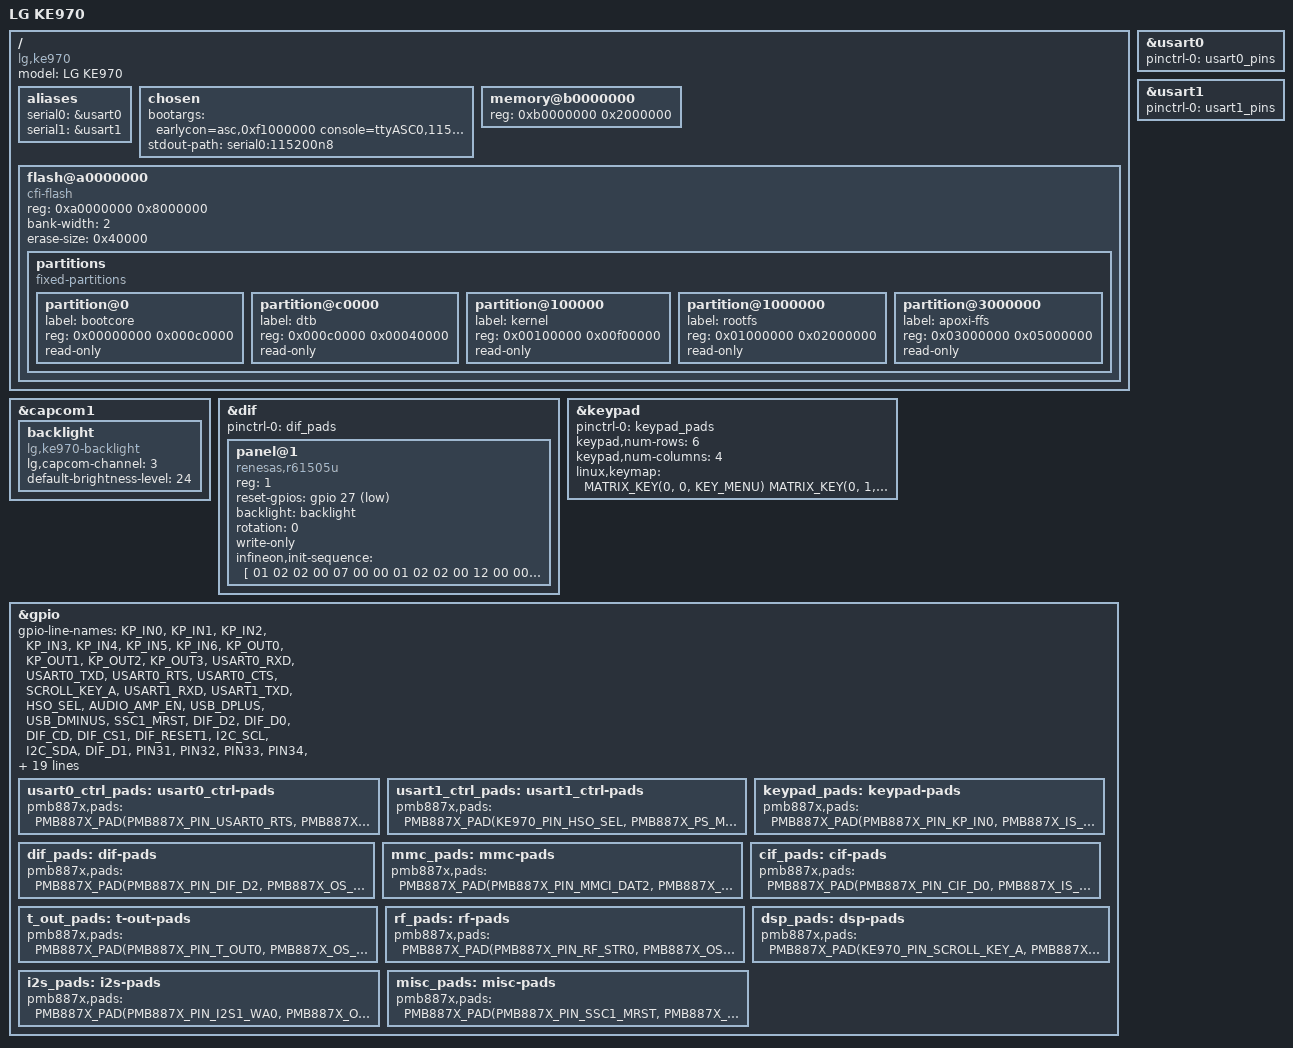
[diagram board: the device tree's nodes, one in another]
// SPDX-License-Identifier: GPL-2.0
/dts-v1/;
#include "pmb8876.dtsi"

#include <dt-bindings/gpio/gpio.h>
#include <dt-bindings/input/input.h>
#include <dt-bindings/pinctrl/pmb887x.h>
#include "ke970-pins.h"

/ {
	model = "LG KE970";
	compatible = "lg,ke970", "infineon,pmb8876";
	
	aliases {
		serial0 = &usart0;
		serial1 = &usart1;
	};
	
	chosen {
		bootargs = "earlycon=asc,0xf1000000 console=ttyASC0,115200n8 ignore_loglevel root=mtd:rootfs rootfstype=cramfs ro";
		stdout-path = "serial0:115200n8";
	};
	
	/* RAM */
	memory@b0000000 {
		device_type = "memory";
		reg = <0xb0000000 0x2000000>;
	};

	/* NOR Flash */
	flash@a0000000 {
		compatible = "cfi-flash";
		reg = <0xa0000000 0x8000000>;
		bank-width = <2>;
		erase-size = <0x40000>;

		partitions {
			compatible = "fixed-partitions";
			#address-cells = <1>;
			#size-cells = <1>;

			partition@0 {
				label = "bootcore";
				reg = <0x00000000 0x000c0000>;
				read-only;
			};

			partition@c0000 {
				label = "dtb";
				reg = <0x000c0000 0x00040000>;
				read-only;
			};

			partition@100000 {
				label = "kernel";
				reg = <0x00100000 0x00f00000>;
				read-only;
			};

			partition@1000000 {
				label = "rootfs";
				reg = <0x01000000 0x02000000>;
				read-only;
			};

			partition@3000000 {
				label = "apoxi-ffs";
				reg = <0x03000000 0x05000000>;
				read-only;
			};
		};
	};
};

/* Usart at "nano" connector */
&usart0 {
	status = "okay";
	pinctrl-names = "default";
	pinctrl-0 = <&usart0_pins>;
};

/* Usart for debug */
&usart1 {
	status = "okay";
	pinctrl-names = "default";
	pinctrl-0 = <&usart1_pins>;
};

/* MAX8645Y single-wire pulse dimming on CC3, pad LCD_BACKLIGHT (ALT2 output) */
&capcom1 {
	backlight: backlight {
		compatible = "lg,ke970-backlight";
		lg,capcom-channel = <3>;
		default-brightness-level = <24>;
	};
};

/* IL220 module: 240x320 R61505U (ILI9320-class) controller on DIF CS1. */
&dif {
	status = "okay";
	pinctrl-names = "default";
	pinctrl-0 = <&dif_pads>;

	panel@1 {
		compatible = "renesas,r61505u";
		reg = <1>;
		reset-gpios = <&gpio 27 GPIO_ACTIVE_LOW>;
		backlight = <&backlight>;
		rotation = <0>;
		write-only;
		infineon,init-sequence = [
			01 02 02 00 07 00 00       /* R07 = 0x0000 */
			01 02 02 00 12 00 00       /* R12 = 0x0000 */
			02 09                      /* wait 9 ms */
			01 02 00 00 00             /* R00 index write (oscillator wake-up) */
			01 02 00 00 00             /* R00 index write (oscillator wake-up) */
			01 02 00 00 00             /* R00 index write (oscillator wake-up) */
			01 02 00 00 00             /* R00 index write (oscillator wake-up) */
			01 02 02 00 00 00 01       /* R00 = 0x0001 (OSC on) */
			02 0a                      /* wait 10 ms */
			01 02 02 00 a4 00 01       /* RA4 = 0x0001 */
			01 02 02 00 60 27 00       /* R60 = 0x2700 */
			01 02 02 00 08 02 0e       /* R08 = 0x020E */
			01 02 02 00 30 07 00       /* R30 = 0x0700 */
			01 02 02 00 31 02 00       /* R31 = 0x0200 */
			01 02 02 00 32 02 02       /* R32 = 0x0202 */
			01 02 02 00 33 00 03       /* R33 = 0x0003 */
			01 02 02 00 34 03 03       /* R34 = 0x0303 */
			01 02 02 00 35 07 07       /* R35 = 0x0707 */
			01 02 02 00 36 1f 1f       /* R36 = 0x1F1F */
			01 02 02 00 37 05 06       /* R37 = 0x0506 */
			01 02 02 00 38 02 02       /* R38 = 0x0202 */
			01 02 02 00 39 02 02       /* R39 = 0x0202 */
			01 02 02 00 3a 01 03       /* R3A = 0x0103 */
			01 02 02 00 3b 03 03       /* R3B = 0x0303 */
			01 02 02 00 3c 07 03       /* R3C = 0x0703 */
			01 02 02 00 3d 1f 1f       /* R3D = 0x1F1F */
			02 09                      /* wait 9 ms */
			01 02 02 00 07 00 01       /* R07 = 0x0001 */
			01 02 02 00 17 00 01       /* R17 = 0x0001 */
			01 02 02 00 10 10 b0       /* R10 = 0x10B0 */
			01 02 02 00 11 01 17       /* R11 = 0x0117 */
			01 02 02 00 12 01 1a       /* R12 = 0x011A */
			01 02 02 00 13 0a 00       /* R13 = 0x0A00 */
			01 02 02 00 29 00 0b       /* R29 = 0x000B */
			01 02 02 00 12 01 3a       /* R12 = 0x013A */
			01 02 02 00 01 05 00       /* R01 = 0x0500 */
			01 02 02 00 02 07 00       /* R02 = 0x0700 */
			01 02 02 00 03 50 30       /* R03 = 0x5030 */
			01 02 02 00 04 00 00       /* R04 = 0x0000 */
			01 02 02 00 09 00 01       /* R09 = 0x0001 */
			01 02 02 00 0a 00 08       /* R0A = 0x0008 */
			01 02 02 00 0d 00 0e       /* R0D = 0x000E */
			01 02 02 00 50 00 00       /* R50 = 0x0000 */
			01 02 02 00 51 00 ef       /* R51 = 0x00EF */
			01 02 02 00 52 00 00       /* R52 = 0x0000 */
			01 02 02 00 53 01 3f       /* R53 = 0x013F */
			01 02 02 00 61 00 00       /* R61 = 0x0000 */
			01 02 02 00 90 00 1c       /* R90 = 0x001C */
			01 02 02 00 92 01 00       /* R92 = 0x0100 */
			01 02 02 00 93 00 02       /* R93 = 0x0002 */
			01 02 02 00 20 00 00       /* R20 = 0x0000 */
			01 02 02 00 21 00 00       /* R21 = 0x0000 */
			01 02 02 00 07 00 21       /* R07 = 0x0021 */
			02 0a                      /* wait 10 ms */
			01 02 02 00 07 00 61       /* R07 = 0x0061 (display on, VCOM output) */
			02 06                      /* wait 6 ms */
			01 02 02 00 07 01 73       /* R07 = 0x0173 (display on, VCOM output) */
		];
	};
};

/*
 * 6x5 matrix on KP_IN0..5 and KP_OUT0..4, where the fifth column is not a
 * KP_OUT pad but T_OUT7 in its ALT1 output function, configured over in
 * t_out_pads. That column carries only the second stage of the camera side
 * key, so it is left out of the keymap for now; adding it means bumping
 * keypad,num-columns to 5 and mapping (5, 4) to KEY_CAMERA.
 */
&keypad {
	status = "okay";
	pinctrl-names = "default";
	pinctrl-0 = <&keypad_pads>;

	keypad,num-rows = <6>;
	keypad,num-columns = <4>;

	linux,keymap = <
		MATRIX_KEY(0, 0, KEY_MENU)		/* left soft key */
		MATRIX_KEY(0, 1, KEY_ENTER)		/* OK */
		MATRIX_KEY(0, 2, KEY_SEARCH)		/* right soft key */
		MATRIX_KEY(0, 3, KEY_SEND)

		MATRIX_KEY(1, 0, KEY_1)
		MATRIX_KEY(1, 1, KEY_2)
		MATRIX_KEY(1, 2, KEY_3)
		MATRIX_KEY(1, 3, KEY_BACKSPACE)		/* clear */

		MATRIX_KEY(2, 0, KEY_4)
		MATRIX_KEY(2, 1, KEY_5)
		MATRIX_KEY(2, 2, KEY_6)
		MATRIX_KEY(2, 3, KEY_VOLUMEUP)

		MATRIX_KEY(3, 0, KEY_7)
		MATRIX_KEY(3, 1, KEY_8)
		MATRIX_KEY(3, 2, KEY_9)
		MATRIX_KEY(3, 3, KEY_VOLUMEDOWN)

		MATRIX_KEY(4, 0, KEY_NUMERIC_STAR)
		MATRIX_KEY(4, 1, KEY_0)
		MATRIX_KEY(4, 2, KEY_NUMERIC_POUND)
		MATRIX_KEY(4, 3, KEY_MEDIA)		/* music player */

		MATRIX_KEY(5, 0, KEY_LEFT)
		MATRIX_KEY(5, 1, KEY_POWER)		/* end call, also drives PMIC ON */
		MATRIX_KEY(5, 2, KEY_RIGHT)
		MATRIX_KEY(5, 3, KEY_CAMERA_FOCUS)	/* camera side key, half press */
	>;
};

&gpio {
	gpio-line-names = "KP_IN0", "KP_IN1", "KP_IN2", "KP_IN3", "KP_IN4", "KP_IN5", "KP_IN6", "KP_OUT0", "KP_OUT1",
		"KP_OUT2", "KP_OUT3", "USART0_RXD", "USART0_TXD", "USART0_RTS", "USART0_CTS", "SCROLL_KEY_A",
		"USART1_RXD", "USART1_TXD", "HSO_SEL", "AUDIO_AMP_EN", "USB_DPLUS", "USB_DMINUS", "SSC1_MRST",
		"DIF_D2", "DIF_D0", "DIF_CD", "DIF_CS1", "DIF_RESET1", "I2C_SCL", "I2C_SDA", "DIF_D1", "PIN31",
		"PIN32", "PIN33", "PIN34", "PIN35", "PIN36", "PIN37", "I2S1_WA0", "USB_CHG_EN", "MMCI_DAT2",
		"MMCI_DAT3", "PIN42", "T_OUT0", "T_OUT1", "T_OUT2", "T_OUT3", "T_OUT4", "T_OUT5", "T_OUT6", "T_OUT7",
		"JACK_DETECT", "LCD_BACKLIGHT", "T_OUT10", "T_OUT11", "AF_PWR_EN", "RF_STR0", "RF_STR1", "SLIDE_OPEN",
		"RF_CLK", "PIN60", "BT_RESET", "SCROLL_KEY_B", "SIM_EN", "PIN64", "PIN65", "PIPESTAT2", "PIPESTAT1",
		"PIPESTAT0", "TRACEPKT0", "TRACEPKT1", "TRACEPKT2", "TRACEPKT3", "TRACEPKT4", "PIN74", "PIN75", "PIN76",
		"FCDP_RB", "CIF_D0", "CIF_D1", "CIF_D2", "CIF_D3", "CIF_D4", "CIF_D5", "CIF_D6", "CIF_D7", "CIF_PCLK",
		"CIF_HSYNC", "CIF_VSYNC", "CLKOUT2", "CIF_RESET", "DIF_D3", "DIF_D4", "DIF_D5", "DIF_D6", "DIF_D7",
		"LCD_IF_MODE", "DIF_WR", "HOOK_DETECT", "MMCI_DAT1", "DIF_VD", "PIN101", "PIN102",
		"SLIDE_KEY_BACKLIGHT", "MMCI_CMD", "MMCI_DAT0", "MMCI_CLK", "USIF_TXD_MTSR", "PIN108", "SCROLL_EN",
		"RPWRON", "SPK_RCV_SEL", "I2S1_CLK1", "CIF_PD";

	usart0_ctrl_pads: usart0_ctrl-pads {
		pmb887x,pads = <
			PMB887X_PAD(PMB887X_PIN_USART0_RTS, PMB887X_ENAQ_ON)
			PMB887X_PAD(PMB887X_PIN_USART0_CTS, PMB887X_IS_ALT0 | PMB887X_PPEN_OPENDRAIN | PMB887X_PDPU_PULLUP)
		>;
	};

	usart1_ctrl_pads: usart1_ctrl-pads {
		pmb887x,pads = <
			PMB887X_PAD(KE970_PIN_HSO_SEL, PMB887X_PS_MANUAL | PMB887X_DATA_HIGH | PMB887X_DIR_OUT | PMB887X_PDPU_PULLUP)
			PMB887X_PAD(KE970_PIN_AUDIO_AMP_EN, PMB887X_PS_MANUAL | PMB887X_DATA_HIGH | PMB887X_DIR_OUT | PMB887X_PDPU_PULLUP)
		>;
	};

	keypad_pads: keypad-pads {
		pmb887x,pads = <
			PMB887X_PAD(PMB887X_PIN_KP_IN0, PMB887X_IS_ALT0 | PMB887X_PPEN_OPENDRAIN | PMB887X_PDPU_PULLUP)
			PMB887X_PAD(PMB887X_PIN_KP_IN1, PMB887X_IS_ALT0 | PMB887X_PPEN_OPENDRAIN | PMB887X_PDPU_PULLUP)
			PMB887X_PAD(PMB887X_PIN_KP_IN2, PMB887X_IS_ALT0 | PMB887X_PPEN_OPENDRAIN | PMB887X_PDPU_PULLUP)
			PMB887X_PAD(PMB887X_PIN_KP_IN3, PMB887X_IS_ALT0 | PMB887X_PPEN_OPENDRAIN | PMB887X_PDPU_PULLUP)
			PMB887X_PAD(PMB887X_PIN_KP_IN4, PMB887X_IS_ALT0 | PMB887X_PPEN_OPENDRAIN | PMB887X_PDPU_PULLUP)
			PMB887X_PAD(PMB887X_PIN_KP_IN5, PMB887X_IS_ALT0 | PMB887X_PPEN_OPENDRAIN | PMB887X_PDPU_PULLUP)
			PMB887X_PAD(PMB887X_PIN_KP_IN6, PMB887X_PS_MANUAL | PMB887X_DIR_OUT)
			PMB887X_PAD(PMB887X_PIN_KP_OUT0, PMB887X_OS_ALT0 | PMB887X_PPEN_OPENDRAIN)
			PMB887X_PAD(PMB887X_PIN_KP_OUT1, PMB887X_OS_ALT0 | PMB887X_PPEN_OPENDRAIN)
			PMB887X_PAD(PMB887X_PIN_KP_OUT2, PMB887X_OS_ALT0 | PMB887X_PPEN_OPENDRAIN)
			PMB887X_PAD(PMB887X_PIN_KP_OUT3, PMB887X_OS_ALT0 | PMB887X_PPEN_OPENDRAIN)
		>;
	};

	dif_pads: dif-pads {
		pmb887x,pads = <
			PMB887X_PAD(PMB887X_PIN_DIF_D2, PMB887X_OS_ALT0 | PMB887X_PDPU_PULLUP)
			PMB887X_PAD(PMB887X_PIN_DIF_D0, PMB887X_OS_ALT0 | PMB887X_PDPU_PULLUP)
			PMB887X_PAD(PMB887X_PIN_DIF_CD, PMB887X_OS_ALT0 | PMB887X_PDPU_PULLUP)
			PMB887X_PAD(PMB887X_PIN_DIF_CS1, PMB887X_OS_ALT0 | PMB887X_PDPU_PULLUP)
			PMB887X_PAD(PMB887X_PIN_DIF_RESET1, PMB887X_PS_MANUAL | PMB887X_DATA_HIGH | PMB887X_DIR_OUT | PMB887X_PDPU_PULLUP)
			PMB887X_PAD(PMB887X_PIN_DIF_D1, PMB887X_OS_ALT0 | PMB887X_PDPU_PULLUP)
			PMB887X_PAD(KE970_PIN_USB_CHG_EN, PMB887X_IS_ALT0 | PMB887X_OS_ALT0 | PMB887X_PDPU_PULLUP)
			PMB887X_PAD(PMB887X_PIN_DIF_D3, PMB887X_OS_ALT0 | PMB887X_PDPU_PULLUP)
			PMB887X_PAD(PMB887X_PIN_DIF_D4, PMB887X_OS_ALT0 | PMB887X_PDPU_PULLUP)
			PMB887X_PAD(PMB887X_PIN_DIF_D5, PMB887X_OS_ALT0 | PMB887X_PDPU_PULLUP)
			PMB887X_PAD(PMB887X_PIN_DIF_D6, PMB887X_OS_ALT0 | PMB887X_PDPU_PULLUP)
			PMB887X_PAD(PMB887X_PIN_DIF_D7, PMB887X_OS_ALT0 | PMB887X_PDPU_PULLUP)
			PMB887X_PAD(KE970_PIN_LCD_IF_MODE, PMB887X_PS_MANUAL | PMB887X_DATA_HIGH | PMB887X_DIR_OUT)
			PMB887X_PAD(PMB887X_PIN_DIF_WR, PMB887X_OS_ALT0)
			PMB887X_PAD(KE970_PIN_HOOK_DETECT, PMB887X_IS_ALT1 | PMB887X_PPEN_OPENDRAIN | PMB887X_PDPU_PULLUP)
			PMB887X_PAD(PMB887X_PIN_DIF_VD, PMB887X_IS_ALT0 | PMB887X_PDPU_PULLDOWN)
		>;
	};

	mmc_pads: mmc-pads {
		pmb887x,pads = <
			PMB887X_PAD(PMB887X_PIN_MMCI_DAT2, PMB887X_IS_ALT0 | PMB887X_OS_ALT0 | PMB887X_PDPU_PULLUP)
			PMB887X_PAD(PMB887X_PIN_MMCI_DAT3, PMB887X_IS_ALT0 | PMB887X_OS_ALT0 | PMB887X_PDPU_PULLUP)
			PMB887X_PAD(PMB887X_PIN_MMCI_DAT1, PMB887X_PS_MANUAL | PMB887X_DATA_HIGH | PMB887X_DIR_OUT | PMB887X_PDPU_PULLUP)
			PMB887X_PAD(PMB887X_PIN_MMCI_CMD, PMB887X_OS_ALT0)
			PMB887X_PAD(PMB887X_PIN_MMCI_DAT0, PMB887X_OS_ALT0)
			PMB887X_PAD(PMB887X_PIN_MMCI_CLK, PMB887X_IS_ALT0 | PMB887X_OS_ALT0)
		>;
	};

	cif_pads: cif-pads {
		pmb887x,pads = <
			PMB887X_PAD(PMB887X_PIN_CIF_D0, PMB887X_IS_ALT0 | PMB887X_PPEN_OPENDRAIN | PMB887X_PDPU_PULLUP)
			PMB887X_PAD(PMB887X_PIN_CIF_D1, PMB887X_IS_ALT0 | PMB887X_PPEN_OPENDRAIN | PMB887X_PDPU_PULLUP)
			PMB887X_PAD(PMB887X_PIN_CIF_D2, PMB887X_IS_ALT0 | PMB887X_PPEN_OPENDRAIN | PMB887X_PDPU_PULLUP)
			PMB887X_PAD(PMB887X_PIN_CIF_D3, PMB887X_IS_ALT0 | PMB887X_PPEN_OPENDRAIN | PMB887X_PDPU_PULLUP)
			PMB887X_PAD(PMB887X_PIN_CIF_D4, PMB887X_IS_ALT0 | PMB887X_PPEN_OPENDRAIN | PMB887X_PDPU_PULLUP)
			PMB887X_PAD(PMB887X_PIN_CIF_D5, PMB887X_IS_ALT0 | PMB887X_PPEN_OPENDRAIN | PMB887X_PDPU_PULLUP)
			PMB887X_PAD(PMB887X_PIN_CIF_D6, PMB887X_IS_ALT0 | PMB887X_PPEN_OPENDRAIN | PMB887X_PDPU_PULLUP)
			PMB887X_PAD(PMB887X_PIN_CIF_D7, PMB887X_IS_ALT0 | PMB887X_PPEN_OPENDRAIN | PMB887X_PDPU_PULLUP)
			PMB887X_PAD(PMB887X_PIN_CIF_PCLK, PMB887X_IS_ALT0 | PMB887X_PPEN_OPENDRAIN | PMB887X_PDPU_PULLUP)
			PMB887X_PAD(PMB887X_PIN_CIF_HSYNC, PMB887X_IS_ALT0 | PMB887X_PPEN_OPENDRAIN | PMB887X_PDPU_PULLUP)
			PMB887X_PAD(PMB887X_PIN_CIF_VSYNC, PMB887X_IS_ALT0 | PMB887X_PPEN_OPENDRAIN | PMB887X_PDPU_PULLUP)
			PMB887X_PAD(PMB887X_PIN_CIF_RESET, PMB887X_PS_MANUAL | PMB887X_DATA_HIGH | PMB887X_DIR_OUT)
			PMB887X_PAD(PMB887X_PIN_CIF_PD, PMB887X_OS_ALT0)
		>;
	};

	t_out_pads: t-out-pads {
		pmb887x,pads = <
			PMB887X_PAD(PMB887X_PIN_T_OUT0, PMB887X_OS_ALT0)
			PMB887X_PAD(PMB887X_PIN_T_OUT1, PMB887X_PS_MANUAL | PMB887X_DIR_OUT | PMB887X_PDPU_PULLDOWN)
			PMB887X_PAD(PMB887X_PIN_T_OUT2, PMB887X_OS_ALT0 | PMB887X_PDPU_PULLDOWN)
			PMB887X_PAD(PMB887X_PIN_T_OUT3, PMB887X_OS_ALT0 | PMB887X_PDPU_PULLDOWN)
			PMB887X_PAD(PMB887X_PIN_T_OUT4, PMB887X_OS_ALT0 | PMB887X_PDPU_PULLDOWN)
			PMB887X_PAD(PMB887X_PIN_T_OUT5, PMB887X_PS_MANUAL | PMB887X_DIR_OUT)
			PMB887X_PAD(PMB887X_PIN_T_OUT6, PMB887X_OS_ALT0 | PMB887X_PDPU_PULLDOWN)
			PMB887X_PAD(KE970_PIN_KP_OUT4, PMB887X_OS_ALT1 | PMB887X_PPEN_OPENDRAIN)
			PMB887X_PAD(KE970_PIN_JACK_DETECT, PMB887X_IS_ALT4 | PMB887X_PPEN_OPENDRAIN | PMB887X_PDPU_PULLUP)
			PMB887X_PAD(KE970_PIN_LCD_BACKLIGHT, PMB887X_OS_ALT2)
			PMB887X_PAD(PMB887X_PIN_T_OUT10, PMB887X_PS_MANUAL)
			PMB887X_PAD(PMB887X_PIN_T_OUT11, PMB887X_PS_MANUAL | PMB887X_DIR_OUT)
			PMB887X_PAD(KE970_PIN_AF_PWR_EN, PMB887X_PS_MANUAL | PMB887X_DIR_OUT)
		>;
	};

	rf_pads: rf-pads {
		pmb887x,pads = <
			PMB887X_PAD(PMB887X_PIN_RF_STR0, PMB887X_OS_ALT0 | PMB887X_PPEN_OPENDRAIN | PMB887X_PDPU_PULLUP)
			PMB887X_PAD(PMB887X_PIN_RF_STR1, PMB887X_IS_ALT2)
			PMB887X_PAD(KE970_PIN_SLIDE_OPEN, PMB887X_IS_ALT2 | PMB887X_PPEN_OPENDRAIN)
			PMB887X_PAD(PMB887X_PIN_RF_CLK, PMB887X_OS_ALT1)
			PMB887X_PAD(PMB887X_PIN_CLKOUT2, PMB887X_OS_ALT0 | PMB887X_PDPU_PULLUP)
		>;
	};

	dsp_pads: dsp-pads {
		pmb887x,pads = <
			PMB887X_PAD(KE970_PIN_SCROLL_KEY_A, PMB887X_IS_ALT2 | PMB887X_PPEN_OPENDRAIN | PMB887X_PDPU_PULLUP)
			PMB887X_PAD(KE970_PIN_BT_RESET, PMB887X_PS_MANUAL | PMB887X_DIR_OUT)
			PMB887X_PAD(KE970_PIN_SCROLL_KEY_B, PMB887X_IS_ALT3 | PMB887X_PPEN_OPENDRAIN)
		>;
	};

	i2s_pads: i2s-pads {
		pmb887x,pads = <
			PMB887X_PAD(PMB887X_PIN_I2S1_WA0, PMB887X_OS_ALT0)
			PMB887X_PAD(KE970_PIN_SLIDE_KEY_BACKLIGHT, PMB887X_PS_MANUAL | PMB887X_DIR_OUT)
			PMB887X_PAD(PMB887X_PIN_I2S1_CLK1, PMB887X_PS_MANUAL | PMB887X_DIR_OUT)
		>;
	};

	misc_pads: misc-pads {
		pmb887x,pads = <
			PMB887X_PAD(PMB887X_PIN_SSC1_MRST, PMB887X_IS_ALT2 | PMB887X_PPEN_OPENDRAIN)
			PMB887X_PAD(PMB887X_PIN_PIN31, PMB887X_PS_MANUAL | PMB887X_DIR_OUT)
			PMB887X_PAD(PMB887X_PIN_PIN32, PMB887X_PS_MANUAL | PMB887X_DIR_OUT | PMB887X_PDPU_PULLUP)
			PMB887X_PAD(PMB887X_PIN_PIN33, PMB887X_PS_MANUAL | PMB887X_DIR_OUT | PMB887X_PDPU_PULLUP)
			PMB887X_PAD(PMB887X_PIN_PIN34, PMB887X_PS_MANUAL | PMB887X_DIR_OUT)
			PMB887X_PAD(PMB887X_PIN_PIN35, PMB887X_OS_ALT0)
			PMB887X_PAD(PMB887X_PIN_PIN36, PMB887X_IS_ALT0 | PMB887X_PPEN_OPENDRAIN)
			PMB887X_PAD(PMB887X_PIN_PIN37, PMB887X_OS_ALT0)
			PMB887X_PAD(PMB887X_PIN_PIN42, PMB887X_IS_ALT0 | PMB887X_PPEN_OPENDRAIN | PMB887X_PDPU_PULLDOWN)
			PMB887X_PAD(PMB887X_PIN_PIN60, PMB887X_OS_ALT0)
			PMB887X_PAD(PMB887X_PIN_FCDP_RB, PMB887X_IS_ALT0 | PMB887X_PPEN_OPENDRAIN | PMB887X_PDPU_PULLUP)
			PMB887X_PAD(PMB887X_PIN_PIN101, PMB887X_IS_ALT2 | PMB887X_PPEN_OPENDRAIN | PMB887X_PDPU_PULLUP)
			PMB887X_PAD(PMB887X_PIN_PIN102, PMB887X_PS_MANUAL | PMB887X_DIR_OUT)
			PMB887X_PAD(PMB887X_PIN_USIF_TXD_MTSR, PMB887X_OS_ALT0 | PMB887X_PDPU_PULLUP)
			PMB887X_PAD(PMB887X_PIN_PIN108, PMB887X_IS_ALT0 | PMB887X_PPEN_OPENDRAIN | PMB887X_PDPU_PULLUP)
			PMB887X_PAD(KE970_PIN_SCROLL_EN, PMB887X_PS_MANUAL)
			PMB887X_PAD(KE970_PIN_RPWRON, PMB887X_PS_MANUAL | PMB887X_PPEN_OPENDRAIN)
			PMB887X_PAD(KE970_PIN_SPK_RCV_SEL, PMB887X_PS_MANUAL | PMB887X_DIR_OUT | PMB887X_PDPU_PULLUP)
		>;
	};

};
